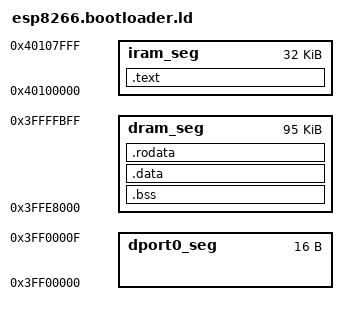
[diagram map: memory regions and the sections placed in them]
/*
Linker file used to link the bootloader.
*/


/* Simplified memory map for the bootloader

   The main purpose is to make sure the bootloader can load into main memory
   without overwriting itself.
*/
MEMORY
{
  dport0_seg :    org = 0x3FF00000, len = 0x10

  /* All .data/.bss/heap are in this segment. Reserve 1KB for old boot or ROM boot */
  dram_seg  :    org = 0x3FFE8000, len = 0x18000 - 0x400

  /* Functions which are critical should be put in this segment. */
  iram_seg  :    org = 0x40100000, len = 0x8000
}

/*  Default entry point:  */
ENTRY(call_start_cpu);

SECTIONS
{
  .text :
  {
    _stext = .;
    _text_start = ABSOLUTE(.);
    . = ALIGN (16);
    *(.entry.text)
    *(.init.literal)
    *(.init)
    *(.literal .text .literal.* .text.* .stub .gnu.warning .gnu.linkonce.literal.* .gnu.linkonce.t.*.literal .gnu.linkonce.t.*)
    *(.iram1 .iram1.*) /* catch stray IRAM_ATTR */
    *(.fini.literal)
    *(.fini)
    *(.gnu.version)
    _text_end = ABSOLUTE(.);
    _etext = .;
  } > iram_seg

  /* Shared RAM */
  .bss (NOLOAD) :
  {
    . = ALIGN (8);
    _bss_start = ABSOLUTE(.);
    *(.dynsbss)
    *(.sbss)
    *(.sbss.*)
    *(.gnu.linkonce.sb.*)
    *(.scommon)
    *(.sbss2)
    *(.sbss2.*)
    *(.gnu.linkonce.sb2.*)
    *(.dynbss)
    *(.bss)
    *(.bss.*)
    *(.gnu.linkonce.b.*)
    *(COMMON)
    . = ALIGN (8);
    _bss_end = ABSOLUTE(.);
  } >dram_seg

  .data :
  {
    _data_start = ABSOLUTE(.);
    *(.data)
    *(.data.*)
    *(.gnu.linkonce.d.*)
    *(.data1)
    *(.sdata)
    *(.sdata.*)
    *(.gnu.linkonce.s.*)
    *(.sdata2)
    *(.sdata2.*)
    *(.gnu.linkonce.s2.*)
    *(.jcr)
    _data_end = ABSOLUTE(.);
  } >dram_seg

  .rodata :
  {
    _rodata_start = ABSOLUTE(.);
    *(.rodata)
    *(.rodata.*)
    *(.gnu.linkonce.r.*)
    *(.rodata1)
    __XT_EXCEPTION_TABLE_ = ABSOLUTE(.);
    *(.xt_except_table)
    *(.gcc_except_table)
    *(.gnu.linkonce.e.*)
    *(.gnu.version_r)
    *(.eh_frame)
    . = (. + 3) & ~ 3;
    /*  C++ constructor and destructor tables, properly ordered:  */
    __init_array_start = ABSOLUTE(.);
    KEEP (*crtbegin.o(.ctors))
    KEEP (*(EXCLUDE_FILE (*crtend.o) .ctors))
    KEEP (*(SORT(.ctors.*)))
    KEEP (*(.ctors))
    __init_array_end = ABSOLUTE(.);
    KEEP (*crtbegin.o(.dtors))
    KEEP (*(EXCLUDE_FILE (*crtend.o) .dtors))
    KEEP (*(SORT(.dtors.*)))
    KEEP (*(.dtors))
    /*  C++ exception handlers table:  */
    __XT_EXCEPTION_DESCS_ = ABSOLUTE(.);
    *(.xt_except_desc)
    *(.gnu.linkonce.h.*)
    __XT_EXCEPTION_DESCS_END__ = ABSOLUTE(.);
    *(.xt_except_desc_end)
    *(.dynamic)
    *(.gnu.version_d)
    _rodata_end = ABSOLUTE(.);
    /* Literals are also RO data. */
    _lit4_start = ABSOLUTE(.);
    *(*.lit4)
    *(.lit4.*)
    *(.gnu.linkonce.lit4.*)
    _lit4_end = ABSOLUTE(.);
    . = ALIGN(4);
    _heap_start = ABSOLUTE(.);
  } >dram_seg
}

PROVIDE ( rtc_sys_info = 0x60001100 );
